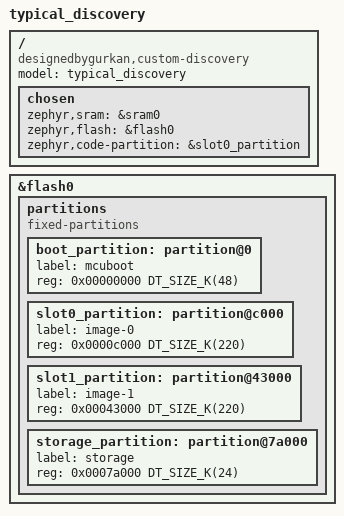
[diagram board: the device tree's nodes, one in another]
/dts-v1/;
#include <nordic/nrf52833_qiaa.dtsi>
#include "custom_discovery-pinctrl.dtsi"

/ {
	model = "typical_discovery";
	compatible = "designedbygurkan,custom-discovery";

	chosen {
		zephyr,sram = &sram0;
		zephyr,flash = &flash0;
		zephyr,code-partition = &slot0_partition;
	};
};

&flash0 {
	partitions {
		compatible = "fixed-partitions";
		#address-cells = <1>;
		#size-cells = <1>;

		boot_partition: partition@0 {
			label = "mcuboot";
			reg = <0x00000000 DT_SIZE_K(48)>;
		};

		slot0_partition: partition@c000 {
			label = "image-0";
			reg = <0x0000c000 DT_SIZE_K(220)>;
		};

		slot1_partition: partition@43000 {
			label = "image-1";
			reg = <0x00043000 DT_SIZE_K(220)>;
		};

		storage_partition: partition@7a000 {
			label = "storage";
			reg = <0x0007a000 DT_SIZE_K(24)>;
		};
	};
};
